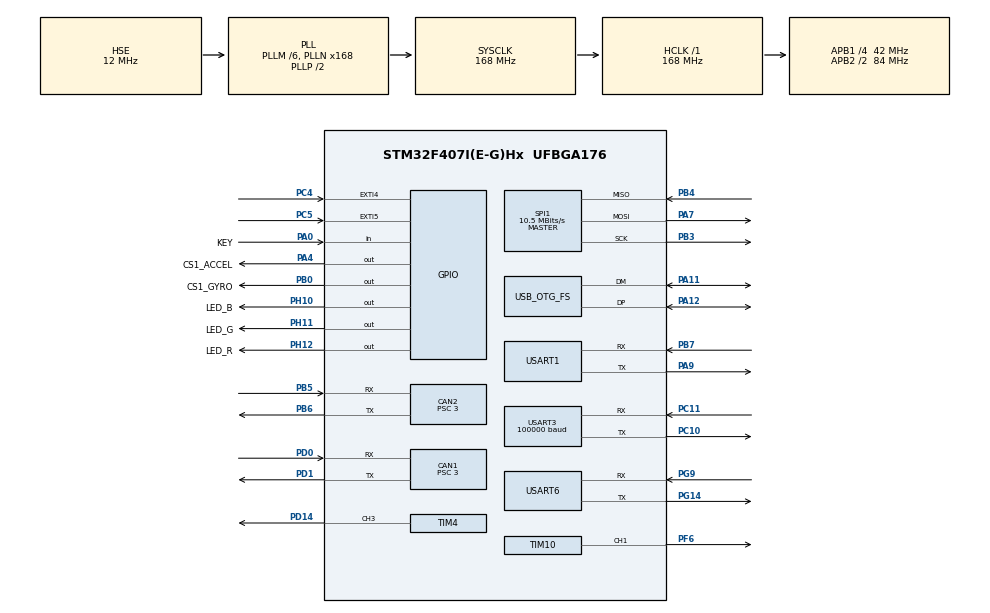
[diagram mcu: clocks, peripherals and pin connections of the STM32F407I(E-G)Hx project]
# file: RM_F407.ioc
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CAN1.ABOM=ENABLE
CAN1.BS1=CAN_BS1_11TQ
CAN1.BS2=CAN_BS2_2TQ
CAN1.CalculateBaudRate=1000000
CAN1.CalculateTimeBit=1000
CAN1.CalculateTimeQuantum=71.42857142857143
CAN1.Prescaler=3
CAN2.ABOM=ENABLE
CAN2.BS1=CAN_BS1_11TQ
CAN2.BS2=CAN_BS2_2TQ
CAN2.CalculateBaudRate=1000000
CAN2.CalculateTimeBit=1000
CAN2.CalculateTimeQuantum=71.42857142857143
CAN2.Prescaler=3
Dma.Request0=USART1_RX
Dma.Request1=USART1_TX
Dma.Request2=SPI1_RX
Dma.Request3=SPI1_TX
Dma.Request4=USART6_RX
Dma.Request5=USART6_TX
Dma.Request6=USART3_RX
Dma.SPI1_RX.2.Direction=DMA_PERIPH_TO_MEMORY
Dma.SPI1_RX.2.FIFOMode=DMA_FIFOMODE_DISABLE
Dma.SPI1_RX.2.Instance=DMA2_Stream0
Dma.SPI1_RX.2.MemDataAlignment=DMA_MDATAALIGN_BYTE
Dma.SPI1_RX.2.MemInc=DMA_MINC_ENABLE
Dma.SPI1_RX.2.Mode=DMA_NORMAL
Dma.SPI1_RX.2.PeriphDataAlignment=DMA_PDATAALIGN_BYTE
Dma.SPI1_RX.2.PeriphInc=DMA_PINC_DISABLE
Dma.SPI1_RX.2.Priority=DMA_PRIORITY_LOW
Dma.SPI1_TX.3.Direction=DMA_MEMORY_TO_PERIPH
Dma.SPI1_TX.3.FIFOMode=DMA_FIFOMODE_DISABLE
Dma.SPI1_TX.3.Instance=DMA2_Stream3
Dma.SPI1_TX.3.MemDataAlignment=DMA_MDATAALIGN_BYTE
Dma.SPI1_TX.3.MemInc=DMA_MINC_ENABLE
Dma.SPI1_TX.3.Mode=DMA_NORMAL
Dma.SPI1_TX.3.PeriphDataAlignment=DMA_PDATAALIGN_BYTE
Dma.SPI1_TX.3.PeriphInc=DMA_PINC_DISABLE
Dma.SPI1_TX.3.Priority=DMA_PRIORITY_LOW
Dma.USART1_RX.0.Direction=DMA_PERIPH_TO_MEMORY
Dma.USART1_RX.0.FIFOMode=DMA_FIFOMODE_DISABLE
Dma.USART1_RX.0.Instance=DMA2_Stream2
Dma.USART1_RX.0.MemDataAlignment=DMA_MDATAALIGN_BYTE
Dma.USART1_RX.0.MemInc=DMA_MINC_ENABLE
Dma.USART1_RX.0.Mode=DMA_NORMAL
Dma.USART1_RX.0.PeriphDataAlignment=DMA_PDATAALIGN_BYTE
Dma.USART1_RX.0.PeriphInc=DMA_PINC_DISABLE
Dma.USART1_RX.0.Priority=DMA_PRIORITY_VERY_HIGH
Dma.USART1_TX.1.Direction=DMA_MEMORY_TO_PERIPH
Dma.USART1_TX.1.FIFOMode=DMA_FIFOMODE_DISABLE
Dma.USART1_TX.1.Instance=DMA2_Stream7
Dma.USART1_TX.1.MemDataAlignment=DMA_MDATAALIGN_BYTE
Dma.USART1_TX.1.MemInc=DMA_MINC_ENABLE
Dma.USART1_TX.1.Mode=DMA_NORMAL
Dma.USART1_TX.1.PeriphDataAlignment=DMA_PDATAALIGN_BYTE
Dma.USART1_TX.1.PeriphInc=DMA_PINC_DISABLE
Dma.USART1_TX.1.Priority=DMA_PRIORITY_HIGH
Dma.USART3_RX.6.Direction=DMA_PERIPH_TO_MEMORY
Dma.USART3_RX.6.FIFOMode=DMA_FIFOMODE_DISABLE
Dma.USART3_RX.6.Instance=DMA1_Stream1
Dma.USART3_RX.6.MemDataAlignment=DMA_MDATAALIGN_BYTE
Dma.USART3_RX.6.MemInc=DMA_MINC_ENABLE
Dma.USART3_RX.6.Mode=DMA_NORMAL
Dma.USART3_RX.6.PeriphDataAlignment=DMA_PDATAALIGN_BYTE
Dma.USART3_RX.6.PeriphInc=DMA_PINC_DISABLE
Dma.USART3_RX.6.Priority=DMA_PRIORITY_VERY_HIGH
Dma.USART6_RX.4.Direction=DMA_PERIPH_TO_MEMORY
Dma.USART6_RX.4.FIFOMode=DMA_FIFOMODE_DISABLE
Dma.USART6_RX.4.Instance=DMA2_Stream1
Dma.USART6_RX.4.MemDataAlignment=DMA_MDATAALIGN_BYTE
Dma.USART6_RX.4.MemInc=DMA_MINC_ENABLE
Dma.USART6_RX.4.Mode=DMA_NORMAL
Dma.USART6_RX.4.PeriphDataAlignment=DMA_PDATAALIGN_BYTE
Dma.USART6_RX.4.PeriphInc=DMA_PINC_DISABLE
Dma.USART6_RX.4.Priority=DMA_PRIORITY_LOW
Dma.USART6_TX.5.Direction=DMA_MEMORY_TO_PERIPH
Dma.USART6_TX.5.FIFOMode=DMA_FIFOMODE_DISABLE
Dma.USART6_TX.5.Instance=DMA2_Stream6
Dma.USART6_TX.5.MemDataAlignment=DMA_MDATAALIGN_BYTE
Dma.USART6_TX.5.MemInc=DMA_MINC_ENABLE
Dma.USART6_TX.5.Mode=DMA_NORMAL
Dma.USART6_TX.5.PeriphDataAlignment=DMA_PDATAALIGN_BYTE
Dma.USART6_TX.5.PeriphInc=DMA_PINC_DISABLE
Dma.USART6_TX.5.Priority=DMA_PRIORITY_LOW
FREERTOS.Tasks01=System_Service,16,256,System_Service_Task,As weak,NULL,Dynamic,NULL,NULL;BMI088,24,2048,BMI088_Task,As weak,NULL,Dynamic,NULL,NULL;Motor,34,512,Motor_Task,As weak,NULL,Dynamic,NULL,NULL;IMU_Service,32,512,IMU_Service_Task,As weak,NULL,Dynamic,NULL,NULL;Key,16,256,Key_Task,As weak,NULL,Dynamic,NULL,NULL;Calibration,24,512,Calibration_Task,As weak,NULL,Dynamic,NULL,NULL;LED,8,256,LED_Task,As weak,NULL,Dynamic,NULL,NULL;USB_Output,8,1024,USB_Output_Task,As weak,NULL,Dynamic,NULL,NULL
FREERTOS.configCHECK_FOR_STACK_OVERFLOW=2
FREERTOS.configTOTAL_HEAP_SIZE=32768
FREERTOS.configUSE_MALLOC_FAILED_HOOK=1
FREERTOS.configUSE_OS2_TIMER=0
Mcu.Family=STM32F4
Mcu.Name=STM32F407I(E-G)Hx
Mcu.Package=UFBGA176
NVIC.CAN1_RX0_IRQn=true\:5\:0\:false\:false\:true\:true\:true\:true\:true
NVIC.CAN1_RX1_IRQn=true\:5\:0\:false\:false\:true\:true\:true\:true\:true
NVIC.CAN2_RX0_IRQn=true\:5\:0\:false\:false\:true\:true\:true\:true\:true
NVIC.DMA1_Stream1_IRQn=true\:5\:0\:false\:false\:true\:true\:false\:true\:true
NVIC.DMA2_Stream0_IRQn=true\:5\:0\:false\:false\:true\:true\:false\:true\:true
NVIC.DMA2_Stream1_IRQn=true\:5\:0\:false\:false\:true\:true\:false\:true\:true
NVIC.DMA2_Stream2_IRQn=true\:5\:0\:false\:false\:true\:true\:false\:true\:true
NVIC.DMA2_Stream3_IRQn=true\:5\:0\:false\:false\:true\:true\:false\:true\:true
NVIC.DMA2_Stream6_IRQn=true\:5\:0\:false\:false\:true\:true\:false\:true\:true
NVIC.DMA2_Stream7_IRQn=true\:5\:0\:false\:false\:true\:true\:false\:true\:true
NVIC.EXTI4_IRQn=true\:5\:0\:false\:false\:true\:true\:true\:true\:true
NVIC.EXTI9_5_IRQn=true\:5\:0\:false\:false\:true\:true\:true\:true\:true
NVIC.OTG_FS_IRQn=true\:5\:0\:false\:false\:true\:true\:false\:true\:true
NVIC.PriorityGroup=NVIC_PRIORITYGROUP_4
NVIC.TIM8_TRG_COM_TIM14_IRQn=true\:15\:0\:false\:false\:true\:false\:false\:true\:true
NVIC.TimeBase=TIM8_TRG_COM_TIM14_IRQn
NVIC.TimeBaseIP=TIM14
NVIC.USART1_IRQn=true\:5\:0\:false\:false\:true\:true\:true\:true\:true
NVIC.USART3_IRQn=true\:5\:0\:false\:false\:true\:true\:true\:true\:true
NVIC.USART6_IRQn=true\:5\:0\:false\:false\:true\:true\:true\:true\:true
PA0-WKUP.GPIO_Label=KEY
PA0-WKUP.GPIO_PuPd=GPIO_PULLUP
PA0-WKUP.Signal=GPIO_Input
PA11.Mode=Device_Only
PA11.Signal=USB_OTG_FS_DM
PA12.Mode=Device_Only
PA12.Signal=USB_OTG_FS_DP
PA13.Mode=Serial_Wire
PA13.Signal=SYS_JTMS-SWDIO
PA14.Mode=Serial_Wire
PA14.Signal=SYS_JTCK-SWCLK
PA4.GPIO_Label=CS1_ACCEL
PA4.GPIO_Speed=GPIO_SPEED_FREQ_VERY_HIGH
PA4.PinState=GPIO_PIN_SET
PA4.Signal=GPIO_Output
PA7.Mode=Full_Duplex_Master
PA7.Signal=SPI1_MOSI
PA9.Mode=Asynchronous
PA9.Signal=USART1_TX
PB0.GPIO_Label=CS1_GYRO
PB0.GPIO_Speed=GPIO_SPEED_FREQ_VERY_HIGH
PB0.PinState=GPIO_PIN_SET
PB0.Signal=GPIO_Output
PB3.Mode=Full_Duplex_Master
PB3.Signal=SPI1_SCK
PB4.Mode=Full_Duplex_Master
PB4.Signal=SPI1_MISO
PB5.Mode=CAN_Activate
PB5.Signal=CAN2_RX
PB6.Mode=CAN_Activate
PB6.Signal=CAN2_TX
PB7.Mode=Asynchronous
PB7.Signal=USART1_RX
PC10.Mode=Asynchronous
PC10.Signal=USART3_TX
PC11.Mode=Asynchronous
PC11.Signal=USART3_RX
PC4.Signal=GPXTI4
PC5.Signal=GPXTI5
PD0.Mode=CAN_Activate
PD0.Signal=CAN1_RX
PD1.Mode=CAN_Activate
PD1.Signal=CAN1_TX
PD14.Signal=S_TIM4_CH3
PF6.Signal=S_TIM10_CH1
PG14.Mode=Asynchronous
PG14.Signal=USART6_TX
PG9.Mode=Asynchronous
PG9.Signal=USART6_RX
PH0-OSC_IN.Mode=HSE-External-Oscillator
PH0-OSC_IN.Signal=RCC_OSC_IN
PH1-OSC_OUT.Mode=HSE-External-Oscillator
PH1-OSC_OUT.Signal=RCC_OSC_OUT
PH10.GPIO_Label=LED_B
PH10.Signal=GPIO_Output
PH11.GPIO_Label=LED_G
PH11.Signal=GPIO_Output
PH12.GPIO_Label=LED_R
PH12.Signal=GPIO_Output
ProjectManager.HeapSize=0x200
ProjectManager.StackSize=0x400
ProjectManager.TargetToolchain=CMake
RCC.48MHZClocksFreq_Value=48000000
RCC.AHBFreq_Value=168000000
RCC.APB1CLKDivider=RCC_HCLK_DIV4
RCC.APB1Freq_Value=42000000
RCC.APB1TimFreq_Value=84000000
RCC.APB2CLKDivider=RCC_HCLK_DIV2
RCC.APB2Freq_Value=84000000
RCC.APB2TimFreq_Value=168000000
RCC.CortexFreq_Value=168000000
RCC.HCLKFreq_Value=168000000
RCC.HSE_VALUE=12000000
RCC.HSI_VALUE=16000000
RCC.LSE_VALUE=32768
RCC.PLLM=6
RCC.PLLN=168
RCC.PLLQ=7
RCC.SYSCLKFreq_VALUE=168000000
RCC.SYSCLKSource=RCC_SYSCLKSOURCE_PLLCLK
RCC.VCOOutputFreq_Value=336000000
SH.S_TIM10_CH1.0=TIM10_CH1,PWM Generation1 CH1
SH.S_TIM4_CH3.0=TIM4_CH3,PWM Generation3 CH3
SPI1.BaudRatePrescaler=SPI_BAUDRATEPRESCALER_8
SPI1.CLKPhase=SPI_PHASE_2EDGE
SPI1.CLKPolarity=SPI_POLARITY_HIGH
SPI1.CalculateBaudRate=10.5 MBits/s
SPI1.Direction=SPI_DIRECTION_2LINES
SPI1.Mode=SPI_MODE_MASTER
SPI1.VirtualType=VM_MASTER
TIM10.AutoReloadPreload=TIM_AUTORELOAD_PRELOAD_ENABLE
TIM10.Channel=TIM_CHANNEL_1
TIM10.Period=9999
TIM10.Prescaler=167
TIM4.AutoReloadPreload=TIM_AUTORELOAD_PRELOAD_ENABLE
TIM4.Channel-PWM\ Generation3\ CH3=TIM_CHANNEL_3
TIM4.Period=499
TIM4.Prescaler=83
TIM4.Pulse-PWM\ Generation3\ CH3=250
USART1.VirtualMode=VM_ASYNC
USART3.BaudRate=100000
USART3.Mode=MODE_RX
USART3.Parity=PARITY_EVEN
USART3.VirtualMode=VM_ASYNC
USART3.WordLength=WORDLENGTH_9B
USART6.VirtualMode=VM_ASYNC
USB_DEVICE.CLASS_NAME_FS=CDC
USB_DEVICE.VirtualMode-CDC_FS=Cdc
USB_DEVICE.VirtualModeFS=Cdc_FS
USB_OTG_FS.VirtualMode=Device_Only
VP_FREERTOS_VS_CMSIS_V2.Mode=CMSIS_V2
VP_RNG_VS_RNG.Mode=RNG_Activate
VP_SYS_VS_tim14.Mode=TIM14
VP_TIM10_VS_ClockSourceINT.Mode=Enable_Timer
VP_USB_DEVICE_VS_USB_DEVICE_CDC_FS.Mode=CDC_FS
board=custom

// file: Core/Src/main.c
/* USER CODE BEGIN Header */
/**
  ******************************************************************************
  * @file           : main.c
  * @brief          : Main program body
  ******************************************************************************
  * @attention
  *
  * Copyright (c) 2026 STMicroelectronics.
  * All rights reserved.
  *
  * This software is licensed under terms that can be found in the LICENSE file
  * in the root directory of this software component.
  * If no LICENSE file comes with this software, it is provided AS-IS.
  *
  ******************************************************************************
  */
/* USER CODE END Header */
#include "main.h"
#include "cmsis_os.h"
#include "can.h"
#include "dma.h"
#include "rng.h"
#include "spi.h"
#include "tim.h"
#include "usart.h"
#include "usb_device.h"
#include "gpio.h"

/* USER CODE BEGIN Includes */
#include "system_init.h"
/* USER CODE END Includes */

void SystemClock_Config(void);
void MX_FREERTOS_Init(void);

int main(void)
{

  /* MCU Configuration--------------------------------------------------------*/

  /* Reset of all peripherals, Initializes the Flash interface and the Systick. */
  HAL_Init();

  /* Configure the system clock */
  SystemClock_Config();

  /* Initialize all configured peripherals */
  MX_GPIO_Init();
  MX_DMA_Init();
  MX_RNG_Init();
  MX_USART1_UART_Init();
  MX_SPI1_Init();
  MX_TIM4_Init();
  MX_USART6_UART_Init();
  MX_TIM10_Init();
  MX_CAN1_Init();
  MX_USART3_UART_Init();
  MX_CAN2_Init();
  /* USER CODE BEGIN 2 */
  System_Init();
  /* USER CODE END 2 */

  /* Init scheduler */
  osKernelInitialize();  /* Call init function for freertos objects (in cmsis_os2.c) */
  MX_FREERTOS_Init();

  /* Start scheduler */
  osKernelStart();

  /* We should never get here as control is now taken by the scheduler */

  /* Infinite loop */
  while (1)
  {

  }
}

void SystemClock_Config(void)
{
  RCC_OscInitTypeDef RCC_OscInitStruct = {0};
  RCC_ClkInitTypeDef RCC_ClkInitStruct = {0};

  /** Configure the main internal regulator output voltage
  */
  __HAL_RCC_PWR_CLK_ENABLE();
  __HAL_PWR_VOLTAGESCALING_CONFIG(PWR_REGULATOR_VOLTAGE_SCALE1);

  /** Initializes the RCC Oscillators according to the specified parameters
  * in the RCC_OscInitTypeDef structure.
  */
  RCC_OscInitStruct.OscillatorType = RCC_OSCILLATORTYPE_HSE;
  RCC_OscInitStruct.HSEState = RCC_HSE_ON;
  RCC_OscInitStruct.PLL.PLLState = RCC_PLL_ON;
  RCC_OscInitStruct.PLL.PLLSource = RCC_PLLSOURCE_HSE;
  RCC_OscInitStruct.PLL.PLLM = 6;
  RCC_OscInitStruct.PLL.PLLN = 168;
  RCC_OscInitStruct.PLL.PLLP = RCC_PLLP_DIV2;
  RCC_OscInitStruct.PLL.PLLQ = 7;
  if (HAL_RCC_OscConfig(&RCC_OscInitStruct) != HAL_OK)
  {
    Error_Handler();
  }

  /** Initializes the CPU, AHB and APB buses clocks
  */
  RCC_ClkInitStruct.ClockType = RCC_CLOCKTYPE_HCLK|RCC_CLOCKTYPE_SYSCLK
                              |RCC_CLOCKTYPE_PCLK1|RCC_CLOCKTYPE_PCLK2;
  RCC_ClkInitStruct.SYSCLKSource = RCC_SYSCLKSOURCE_PLLCLK;
  RCC_ClkInitStruct.AHBCLKDivider = RCC_SYSCLK_DIV1;
  RCC_ClkInitStruct.APB1CLKDivider = RCC_HCLK_DIV4;
  RCC_ClkInitStruct.APB2CLKDivider = RCC_HCLK_DIV2;

  if (HAL_RCC_ClockConfig(&RCC_ClkInitStruct, FLASH_LATENCY_5) != HAL_OK)
  {
    Error_Handler();
  }
}

void HAL_TIM_PeriodElapsedCallback(TIM_HandleTypeDef *htim)
{
  if (htim->Instance == TIM14)
  {
    HAL_IncTick();
  }
}

void Error_Handler(void)
{
  __disable_irq();
  while (1)
  {
  }
}

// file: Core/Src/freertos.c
/* USER CODE BEGIN Header */
/**
  ******************************************************************************
  * File Name          : freertos.c
  * Description        : Code for freertos applications
  ******************************************************************************
  * @attention
  *
  * Copyright (c) 2026 STMicroelectronics.
  * All rights reserved.
  *
  * This software is licensed under terms that can be found in the LICENSE file
  * in the root directory of this software component.
  * If no LICENSE file comes with this software, it is provided AS-IS.
  *
  ******************************************************************************
  */
/* USER CODE END Header */

#include "FreeRTOS.h"
#include "task.h"
#include "main.h"
#include "cmsis_os.h"

/* USER CODE BEGIN Includes */
#include "led.h"            /* LED_Red()      —— 亮红灯，留下"死因" */
#include "sys_timestamp.h"  /* Sys_Delay_US() —— 让红灯亮够时间再复位 */
/* USER CODE END Includes */

/* Definitions for System_Service */
osThreadId_t System_ServiceHandle;
const osThreadAttr_t System_Service_attributes = {
  .name = "System_Service",
  .stack_size = 256 * 4,
  .priority = (osPriority_t) osPriorityBelowNormal,
};
/* Definitions for BMI088 */
osThreadId_t BMI088Handle;
const osThreadAttr_t BMI088_attributes = {
  .name = "BMI088",
  .stack_size = 2048 * 4,
  .priority = (osPriority_t) osPriorityNormal,
};
/* Definitions for Motor */
osThreadId_t MotorHandle;
const osThreadAttr_t Motor_attributes = {
  .name = "Motor",
  .stack_size = 512 * 4,
  .priority = (osPriority_t) osPriorityAboveNormal2,
};
/* Definitions for IMU_Service */
osThreadId_t IMU_ServiceHandle;
const osThreadAttr_t IMU_Service_attributes = {
  .name = "IMU_Service",
  .stack_size = 512 * 4,
  .priority = (osPriority_t) osPriorityAboveNormal,
};
/* Definitions for Key */
osThreadId_t KeyHandle;
const osThreadAttr_t Key_attributes = {
  .name = "Key",
  .stack_size = 256 * 4,
  .priority = (osPriority_t) osPriorityBelowNormal,
};
/* Definitions for Calibration */
osThreadId_t CalibrationHandle;
const osThreadAttr_t Calibration_attributes = {
  .name = "Calibration",
  .stack_size = 512 * 4,
  .priority = (osPriority_t) osPriorityNormal,
};
/* Definitions for LED */
osThreadId_t LEDHandle;
const osThreadAttr_t LED_attributes = {
  .name = "LED",
  .stack_size = 256 * 4,
  .priority = (osPriority_t) osPriorityLow,
};
/* Definitions for USB_Output */
osThreadId_t USB_OutputHandle;
const osThreadAttr_t USB_Output_attributes = {
  .name = "USB_Output",
  .stack_size = 1024 * 4,
  .priority = (osPriority_t) osPriorityLow,
};

void System_Service_Task(void *argument);
void BMI088_Task(void *argument);
void Motor_Task(void *argument);
void IMU_Service_Task(void *argument);
void Key_Task(void *argument);
void Calibration_Task(void *argument);
void LED_Task(void *argument);
void USB_Output_Task(void *argument);

extern void MX_USB_DEVICE_Init(void);
void MX_FREERTOS_Init(void); /* (MISRA C 2004 rule 8.1) */

/* Hook prototypes */
void vApplicationStackOverflowHook(xTaskHandle xTask, signed char *pcTaskName);
void vApplicationMallocFailedHook(void);

/* USER CODE BEGIN 4 */
/**
 * @brief 任务栈溢出钩子
 * @note  ★ 这个函数是在【中断上下文】里被调用的！
 *           FreeRTOS 在 PendSV 里做任务切换，切换前检查栈有没有被写穿，
 *           发现异常就跳到这里。所以：
 *             · 不能用阻塞式发送
 *             · 不能调用任何 FreeRTOS API（除了专门给中断用的 ...FromISR）
 *
 *        ★ 处理完为什么复位而不是原地死循环：
 *           栈都写穿了，那块 RAM 已经不可信。硬撑着跑只会产生
 *           "更难查的故障"（你这次遇到的 memchr 崩溃就是典型）。
 *           重启后系统至少是干净的。
 *
 *        ★ 怎么知道出过这事：串口只发波形、没有日志，所以只能靠"灯"——
 *           红灯常亮 50ms 然后复位；如果故障反复发生，看到的就是【红灯反复闪】。
 *           要进一步定位（哪个任务、栈用了多少），把它接进内存快照或临时恢复日志。
 */
void vApplicationStackOverflowHook(xTaskHandle xTask, signed char *pcTaskName)
{
  (void)xTask;                                                    /* 用不到，避免告警 */
  (void)pcTaskName;

  LED_Red();                                                      /* ① 红灯常亮 */
  Sys_Delay_US(50000.0f);                                         /* ② 等 50ms 让灯亮够 */
  NVIC_SystemReset();                                             /* ③ 复位 */
}
/* USER CODE END 4 */

/* USER CODE BEGIN 5 */
/**
 * @brief FreeRTOS 堆耗尽钩子
 * @note  走到这里 = 32KB 的 ucHeap 用光了，说明有地方在运行中
 *        不停创建对象（任务/队列/信号量）却没有删。
 *        这个钩子是在【任务上下文】里调用的，比上面那个安全。
 *        同样：红灯亮 50ms 后复位（没有日志可打）。
 */
void vApplicationMallocFailedHook(void)
{
  LED_Red();
  Sys_Delay_US(50000.0f);
  NVIC_SystemReset();
}
/* USER CODE END 5 */

void MX_FREERTOS_Init(void) {

  /* Create the thread(s) */
  /* creation of System_Service */
  System_ServiceHandle = osThreadNew(System_Service_Task, NULL, &System_Service_attributes);

  /* creation of BMI088 */
  BMI088Handle = osThreadNew(BMI088_Task, NULL, &BMI088_attributes);

  /* creation of Motor */
  MotorHandle = osThreadNew(Motor_Task, NULL, &Motor_attributes);

  /* creation of IMU_Service */
  IMU_ServiceHandle = osThreadNew(IMU_Service_Task, NULL, &IMU_Service_attributes);

  /* creation of Key */
  KeyHandle = osThreadNew(Key_Task, NULL, &Key_attributes);

  /* creation of Calibration */
  CalibrationHandle = osThreadNew(Calibration_Task, NULL, &Calibration_attributes);

  /* creation of LED */
  LEDHandle = osThreadNew(LED_Task, NULL, &LED_attributes);

  /* creation of USB_Output */
  USB_OutputHandle = osThreadNew(USB_Output_Task, NULL, &USB_Output_attributes);

}

__weak void System_Service_Task(void *argument)
{
  /* init code for USB_DEVICE */
  MX_USB_DEVICE_Init();
  for(;;)
  {
    osDelay(1);
  }
}

__weak void BMI088_Task(void *argument)
{
  for(;;)
  {
    osDelay(1);
  }
}

__weak void Motor_Task(void *argument)
{
  for(;;)
  {
    osDelay(1);
  }
}

__weak void IMU_Service_Task(void *argument)
{
  for(;;)
  {
    osDelay(1);
  }
}

__weak void Key_Task(void *argument)
{
  for(;;)
  {
    osDelay(1);
  }
}

__weak void Calibration_Task(void *argument)
{
  for(;;)
  {
    osDelay(1);
  }
}

__weak void LED_Task(void *argument)
{
  for(;;)
  {
    osDelay(1);
  }
}

__weak void USB_Output_Task(void *argument)
{
  for(;;)
  {
    osDelay(1);
  }
}
